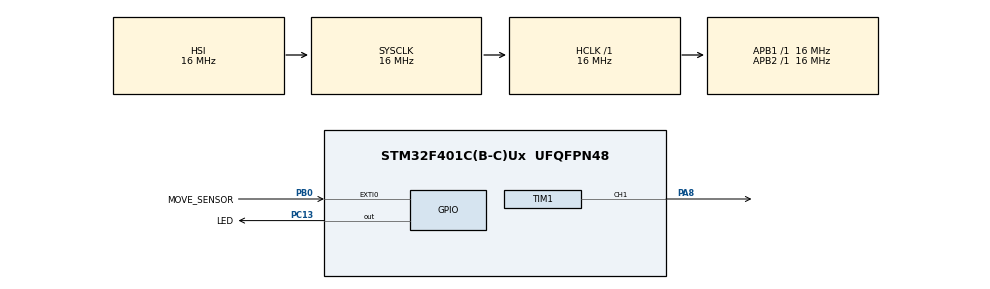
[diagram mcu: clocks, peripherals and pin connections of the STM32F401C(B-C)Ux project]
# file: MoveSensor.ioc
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Dma.Request0=TIM1_CH1
Dma.TIM1_CH1.0.Direction=DMA_MEMORY_TO_PERIPH
Dma.TIM1_CH1.0.FIFOMode=DMA_FIFOMODE_DISABLE
Dma.TIM1_CH1.0.Instance=DMA2_Stream1
Dma.TIM1_CH1.0.MemDataAlignment=DMA_MDATAALIGN_HALFWORD
Dma.TIM1_CH1.0.MemInc=DMA_MINC_ENABLE
Dma.TIM1_CH1.0.Mode=DMA_CIRCULAR
Dma.TIM1_CH1.0.PeriphDataAlignment=DMA_PDATAALIGN_HALFWORD
Dma.TIM1_CH1.0.PeriphInc=DMA_PINC_DISABLE
Dma.TIM1_CH1.0.Priority=DMA_PRIORITY_LOW
Mcu.Family=STM32F4
Mcu.Name=STM32F401C(B-C)Ux
Mcu.Package=UFQFPN48
NVIC.DMA2_Stream1_IRQn=true\:0\:0\:false\:false\:true\:false\:true\:true
NVIC.EXTI0_IRQn=true\:0\:0\:false\:false\:true\:true\:true\:true
NVIC.PriorityGroup=NVIC_PRIORITYGROUP_4
PA8.Signal=S_TIM1_CH1
PB0.GPIO_Label=MOVE_SENSOR
PB0.Signal=GPXTI0
PC13-ANTI_TAMP.GPIO_Label=LED
PC13-ANTI_TAMP.Signal=GPIO_Output
ProjectManager.HeapSize=0x200
ProjectManager.StackSize=0x400
ProjectManager.TargetToolchain=STM32CubeIDE
RCC.AHBFreq_Value=16000000
RCC.APB1Freq_Value=16000000
RCC.APB2Freq_Value=16000000
RCC.CortexFreq_Value=16000000
RCC.HSE_VALUE=25000000
RCC.HSI_VALUE=16000000
RCC.LSE_VALUE=32768
RCC.SYSCLKFreq_VALUE=16000000
RCC.VCOOutputFreq_Value=192000000
SH.S_TIM1_CH1.0=TIM1_CH1,PWM Generation1 CH1
TIM1.Channel-PWM\ Generation1\ CH1=TIM_CHANNEL_1
TIM1.Period=20-1
board=custom

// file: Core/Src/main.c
/* USER CODE BEGIN Header */
/**
  ******************************************************************************
  * @file           : main.c
  * @brief          : Main program body
  ******************************************************************************
  * @attention
  *
  * Copyright (c) 2023 STMicroelectronics.
  * All rights reserved.
  *
  * This software is licensed under terms that can be found in the LICENSE file
  * in the root directory of this software component.
  * If no LICENSE file comes with this software, it is provided AS-IS.
  *
  ******************************************************************************
  */
/* USER CODE END Header */
#include "main.h"
#include "dma.h"
#include "tim.h"
#include "gpio.h"

/* USER CODE BEGIN Includes */

#include "mainApp/app.h"

/* USER CODE END Includes */

void SystemClock_Config(void);

int main(void)
{

  /* MCU Configuration--------------------------------------------------------*/

  /* Reset of all peripherals, Initializes the Flash interface and the Systick. */
  HAL_Init();

  /* Configure the system clock */
  SystemClock_Config();

  /* Initialize all configured peripherals */
  MX_GPIO_Init();
  MX_DMA_Init();
  MX_TIM1_Init();

  /* Infinite loop */
  /* USER CODE BEGIN WHILE */
  while (1)
  {
    loop();
    /* USER CODE END WHILE */

  }
}

void SystemClock_Config(void)
{
  RCC_OscInitTypeDef RCC_OscInitStruct = {0};
  RCC_ClkInitTypeDef RCC_ClkInitStruct = {0};

  /** Configure the main internal regulator output voltage
  */
  __HAL_RCC_PWR_CLK_ENABLE();
  __HAL_PWR_VOLTAGESCALING_CONFIG(PWR_REGULATOR_VOLTAGE_SCALE2);

  /** Initializes the RCC Oscillators according to the specified parameters
  * in the RCC_OscInitTypeDef structure.
  */
  RCC_OscInitStruct.OscillatorType = RCC_OSCILLATORTYPE_HSI;
  RCC_OscInitStruct.HSIState = RCC_HSI_ON;
  RCC_OscInitStruct.HSICalibrationValue = RCC_HSICALIBRATION_DEFAULT;
  RCC_OscInitStruct.PLL.PLLState = RCC_PLL_NONE;
  if (HAL_RCC_OscConfig(&RCC_OscInitStruct) != HAL_OK)
  {
    Error_Handler();
  }

  /** Initializes the CPU, AHB and APB buses clocks
  */
  RCC_ClkInitStruct.ClockType = RCC_CLOCKTYPE_HCLK|RCC_CLOCKTYPE_SYSCLK
                              |RCC_CLOCKTYPE_PCLK1|RCC_CLOCKTYPE_PCLK2;
  RCC_ClkInitStruct.SYSCLKSource = RCC_SYSCLKSOURCE_HSI;
  RCC_ClkInitStruct.AHBCLKDivider = RCC_SYSCLK_DIV1;
  RCC_ClkInitStruct.APB1CLKDivider = RCC_HCLK_DIV1;
  RCC_ClkInitStruct.APB2CLKDivider = RCC_HCLK_DIV1;

  if (HAL_RCC_ClockConfig(&RCC_ClkInitStruct, FLASH_LATENCY_0) != HAL_OK)
  {
    Error_Handler();
  }
}

void Error_Handler(void)
{
  __disable_irq();
  while (1)
  {
  }
}
